# EFR32MG26B611F2048IM48 register map
Vendor: Silicon Labs; Series: EFR32; File version: B
Registers are 32-bit, read-write, reset 0x0 unless marked. A register's access mark holds for its fields unless they carry their own. Offsets are from the block's base; [hi:lo] are bit positions; lines under a group give offsets from that group; {n}, {i} and the like mark numbered series; 'fields as' and 'values as' point back to an identical list.

## GPIO_NS — GPIO_NS Registers
Base 0x5003C000
Same registers: GPIO_S 0x4003C000
0x00 IPVERSION ro reset 0x7
  [31:0] IPVERSION — ip version id
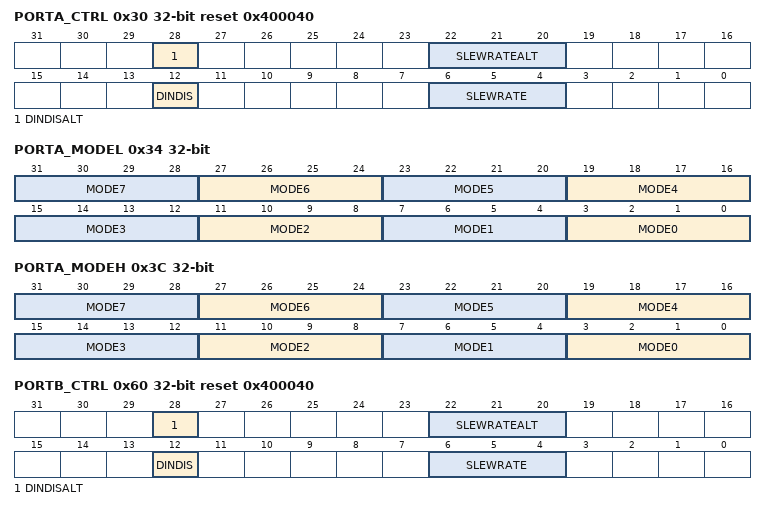
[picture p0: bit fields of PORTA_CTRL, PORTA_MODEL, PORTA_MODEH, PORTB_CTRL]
0x30 PORTA_CTRL reset 0x400040 — Port control
  [28] DINDISALT — Data In Disable Alt
  [22:20] SLEWRATEALT
  [12] DINDIS — Data In Disable
  [6:4] SLEWRATE
0x34 PORTA_MODEL — mode low
  [all] fields
    0=DISABLED (Input disabled. Pullup if DOUT is set.); 1=INPUT (Input enabled. Filter if DOUT is set.); 2=INPUTPULL (Input enabled. DOUT determines pull direction.); 3=INPUTPULLFILTER (Input enabled with filter. DOUT determines pull direction.); 4=PUSHPULL (Push-pull output.); 5=PUSHPULLALT (Push-pull using alternate control.); 6=WIREDOR (Wired-or output.); 7=WIREDORPULLDOWN (Wired-or output with pull-down.); 8=WIREDAND (Open-drain output.); 9=WIREDANDFILTER (Open-drain output with filter.); 10=WIREDANDPULLUP (Open-drain output with pullup.); 11=WIREDANDPULLUPFILTER (Open-drain output with filter and pullup.); 12=WIREDANDALT (Open-drain output using alternate control.); 13=WIREDANDALTFILTER (Open-drain output using alternate control with filter.); 14=WIREDANDALTPULLUP (Open-drain output using alternate control with pullup.); 15=WIREDANDALTPULLUPFILTER (Open-drain output using alternate control with filter and pullup.)
  [4n+3:4n] MODE{n} (n=0..7) — MODE n
0x3C PORTA_MODEH — mode high
  fields as PORTA_MODEL
0x40 PORTA_DOUT — data out
  [15:0] DOUT — Data output
0x44 PORTA_DIN ro — data in
  [15:0] DIN — Data input
0x60 PORTB_CTRL reset 0x400040 — Port control
  fields as PORTA_CTRL
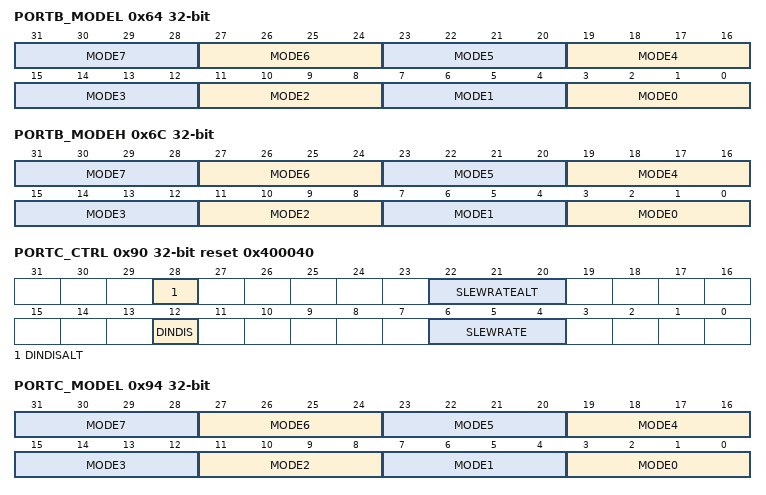
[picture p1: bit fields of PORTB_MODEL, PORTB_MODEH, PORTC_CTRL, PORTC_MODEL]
0x64 PORTB_MODEL — mode low
  fields as PORTA_MODEL
0x6C PORTB_MODEH — mode high
  fields as PORTA_MODEL
0x70 PORTB_DOUT — data out
  [15:0] DOUT — Data output
0x74 PORTB_DIN ro — data in
  [15:0] DIN — Data input
0x90 PORTC_CTRL reset 0x400040 — Port control
  fields as PORTA_CTRL
0x94 PORTC_MODEL — mode low
  fields as PORTA_MODEL
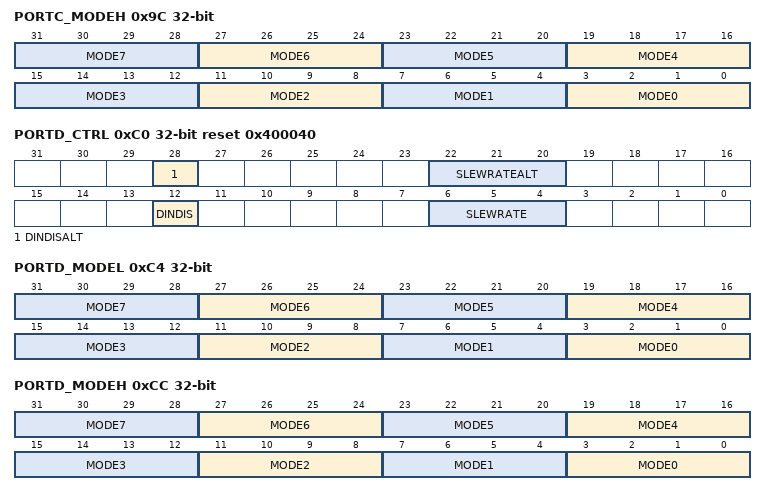
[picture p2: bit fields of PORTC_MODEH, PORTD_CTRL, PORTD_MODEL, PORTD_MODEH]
0x9C PORTC_MODEH — mode high
  fields as PORTA_MODEL
0xA0 PORTC_DOUT — data out
  [15:0] DOUT — Data output
0xA4 PORTC_DIN ro — data in
  [15:0] DIN — Data input
0xC0 PORTD_CTRL reset 0x400040 — Port control
  fields as PORTA_CTRL
0xC4 PORTD_MODEL — mode low
  fields as PORTA_MODEL
0xCC PORTD_MODEH — mode high
  fields as PORTA_MODEL
0xD0 PORTD_DOUT — data out
  [15:0] DOUT — Data output
0xD4 PORTD_DIN ro — data in
  [15:0] DIN — Data input
0x200 LCDSEGL — LCD Segment Enable Low
  [31:0] LCDSEGALLOC — LCD Segment Allocation Low
0x204 LCDSEGH — LCD Segment Enable High
  [7:0] LCDSEGALLOC — LCD Segment Allocation High
0x210 LCDCOM — LCD Common Enable
  [3:0] LCDCOMALLOC — LCD Common Allocation
0x300 LOCK wo reset 0xA534
  [15:0] LOCKKEY — Configuration Lock Key
    0xA534=UNLOCK (Unlock code)
0x310 GPIOLOCKSTATUS ro
  [0] LOCK — GPIO LOCK status
    0=UNLOCKED (Registers are unlocked); 1=LOCKED (Registers are locked)
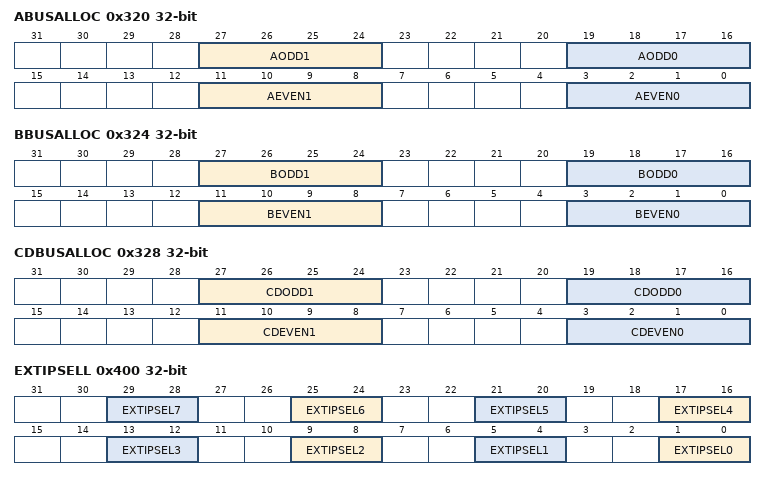
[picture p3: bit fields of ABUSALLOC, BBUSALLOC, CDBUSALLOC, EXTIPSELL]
0x320 ABUSALLOC — A Bus allocation
  [27:24] AODD1 — A Bus Odd 1
    0=TRISTATE (The bus is not allocated); 1=ADC0 (The bus is allocated to ADC0); 2=ACMP0 (The bus is allocated to ACMP0); 3=ACMP1 (The bus is allocated to ACMP1); 4=VDAC0CH1 (The bus is allocated to VDAC0 CH1); 5=VDAC1CH1 (The bus is allocated to VDAC1 CH1)
  [19:16] AODD0 — A Bus Odd 0
    0=TRISTATE (The bus is not allocated); 1=ADC0 (The bus is allocated to ADC0); 2=ACMP0 (The bus is allocated to ACMP0); 3=ACMP1 (The bus is allocated to ACMP1); 4=VDAC0CH0 (The bus is allocated to VDAC0 CH0); 5=VDAC1CH0 (The bus is allocated to VDAC1 CH0)
  [11:8] AEVEN1 — A Bus Even 1
    values as AODD1
  [3:0] AEVEN0 — A Bus Even 0
    values as AODD0
0x324 BBUSALLOC — B Bus allocation
  [27:24] BODD1 — B Bus Odd 1
    values as ABUSALLOC.AODD1
  [19:16] BODD0 — B Bus Odd 0
    values as ABUSALLOC.AODD0
  [11:8] BEVEN1 — B Bus Even 1
    values as ABUSALLOC.AODD1
  [3:0] BEVEN0 — B Bus Even 0
    values as ABUSALLOC.AODD0
0x328 CDBUSALLOC — CD Bus allocation
  [27:24] CDODD1 — CD Bus Odd 1
    values as ABUSALLOC.AODD1
  [19:16] CDODD0 — CD Bus Odd 0
    values as ABUSALLOC.AODD0
  [11:8] CDEVEN1 — CD Bus Even 1
    values as ABUSALLOC.AODD1
  [3:0] CDEVEN0 — CD Bus Even 0
    0=TRISTATE (The bus is not allocated); 1=ADC0 (The bus is allocated to ADC0); 2=ACMP0 (The bus is allocated to ACMP0); 3=ACMP1 (The bus is allocated to ACMP1); 4=VDAC0CH0 (The bus is allocated to VDAC0 CH0); 5=VDAC1CH0 (The bus is allocated to VDAC1 CH0); 11=REPEFUSE (The bus is allocated to Repair EFUSE programming voltage)
0x400 EXTIPSELL — External Interrupt Port Select Low
  [all] fields
    0=PORTA (Port A group selected); 1=PORTB (Port B group selected); 2=PORTC (Port C group selected); 3=PORTD (Port D group selected)
  [4n+1:4n] EXTIPSEL{n} (n=0..7) — External Interrupt Port Select
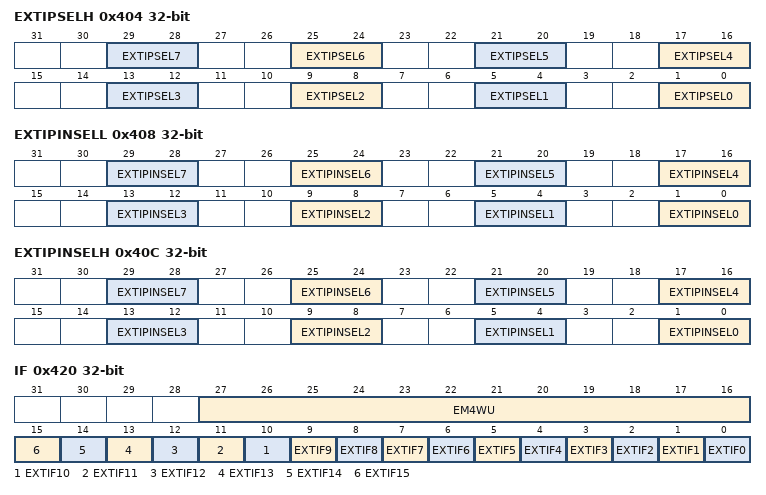
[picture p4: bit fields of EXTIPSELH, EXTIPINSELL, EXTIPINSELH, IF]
0x404 EXTIPSELH — External interrupt Port Select High
  fields as EXTIPSELL
0x408 EXTIPINSELL — External Interrupt Pin Select Low
  [all] fields
    {v}=PIN{v} (OFFSET={v}) (v=0..3)
  [4n+1:4n] EXTIPINSEL{n} (n=0..7) — External Interrupt Pin select
0x40C EXTIPINSELH — External Interrupt Pin Select High
  [all] fields
    {v}=PIN{v+8} (OFFSET={v+8}) (v=0..3)
  [4n+1:4n] EXTIPINSEL{n} (n=0..7) — External Interrupt Pin select
0x410 EXTIRISE — External Interrupt Rising Edge Trigger
  [15:0] EXTIRISE — EXT Int Rise
0x414 EXTIFALL — External Interrupt Falling Edge Trigger
  [15:0] EXTIFALL — EXT Int FALL
0x420 IF — Interrupt Flag
  [27:16] EM4WU — EM4 wake up
  [n] EXTIF{n} (n=0..15) — External Pin Flag
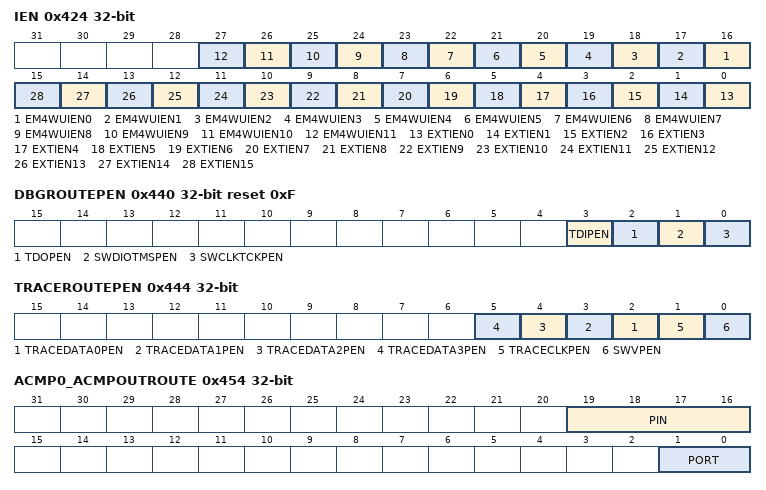
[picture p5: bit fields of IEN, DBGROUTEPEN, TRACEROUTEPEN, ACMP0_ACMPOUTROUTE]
0x424 IEN — Interrupt Enable
  [n+16] EM4WUIEN{n} (n=0..11) — EM4 Wake Up Interrupt En
  [n] EXTIEN{n} (n=0..15) — External Pin Enable
0x42C EM4WUEN
  [27:16] EM4WUEN — EM4 wake up enable
0x430 EM4WUPOL
  [27:16] EM4WUPOL — EM4 Wake-Up Polarity
0x440 DBGROUTEPEN reset 0xF
  [3] TDIPEN — JTAG Test Debug Input Pin Enable
  [2] TDOPEN — JTAG Test Debug Output Pin Enable
  [1] SWDIOTMSPEN — Route Location 0
  [0] SWCLKTCKPEN — Route Pin Enable
0x444 TRACEROUTEPEN
  [n+2] TRACEDATA{n}PEN (n=0..3) — Trace Data{n} Pin Enable
  [1] TRACECLKPEN — Trace Clk Pin Enable
  [0] SWVPEN — Serial Wire Viewer Output Pin Enable
0x450 ACMP0_ROUTEEN — ACMP0 pin enable
  [0] ACMPOUTPEN — ACMPOUT pin enable control bit
0x454 ACMP0_ACMPOUTROUTE — ACMPOUT port/pin select
  [19:16] PIN — ACMPOUT pin select register
  [1:0] PORT — ACMPOUT port select register
0x45C ACMP1_ROUTEEN — ACMP1 pin enable
  [0] ACMPOUTPEN — ACMPOUT pin enable control bit
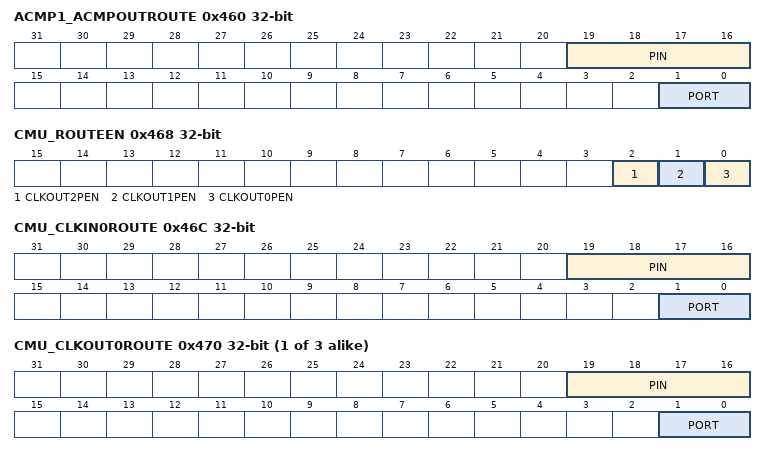
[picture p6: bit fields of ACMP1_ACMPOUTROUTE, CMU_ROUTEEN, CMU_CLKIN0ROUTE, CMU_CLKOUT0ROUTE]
0x460 ACMP1_ACMPOUTROUTE — ACMPOUT port/pin select
  fields as ACMP0_ACMPOUTROUTE
0x468 CMU_ROUTEEN — CMU pin enable
  [2] CLKOUT2PEN — CLKOUT2 pin enable control bit
  [1] CLKOUT1PEN — CLKOUT1 pin enable control bit
  [0] CLKOUT0PEN — CLKOUT0 pin enable control bit
0x46C CMU_CLKIN0ROUTE — CLKIN0 port/pin select
  [19:16] PIN — CLKIN0 pin select register
  [1:0] PORT — CLKIN0 port select register
{0x470+4i} CMU_CLKOUT{i}ROUTE (i=0..2) — CLKOUT{i} port/pin select
  [19:16] PIN — CLKOUT{i} pin select register
  [1:0] PORT — CLKOUT{i} port select register
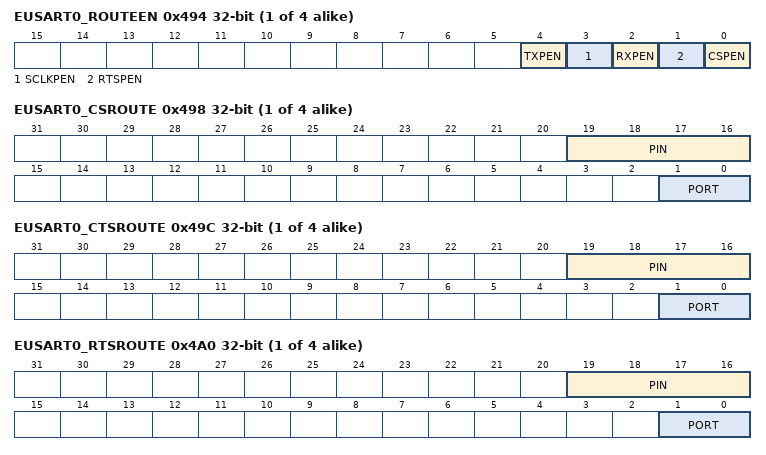
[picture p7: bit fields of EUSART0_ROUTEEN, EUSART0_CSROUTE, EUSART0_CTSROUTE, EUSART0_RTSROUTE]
{0x494+0x20*i} EUSART{i}_ROUTEEN (i=0..3) — EUSART{i} pin enable
  [4] TXPEN — TX pin enable control bit
  [3] SCLKPEN — SCLK pin enable control bit
  [2] RXPEN — RX pin enable control bit
  [1] RTSPEN — RTS pin enable control bit
  [0] CSPEN — CS pin enable control bit
{0x498+0x20*i} EUSART{i}_CSROUTE (i=0..3) — CS port/pin select
  [19:16] PIN — CS pin select register
  [1:0] PORT — CS port select register
{0x49C+0x20*i} EUSART{i}_CTSROUTE (i=0..3) — CTS port/pin select
  [19:16] PIN — CTS pin select register
  [1:0] PORT — CTS port select register
{0x4A0+0x20*i} EUSART{i}_RTSROUTE (i=0..3) — RTS port/pin select
  [19:16] PIN — RTS pin select register
  [1:0] PORT — RTS port select register
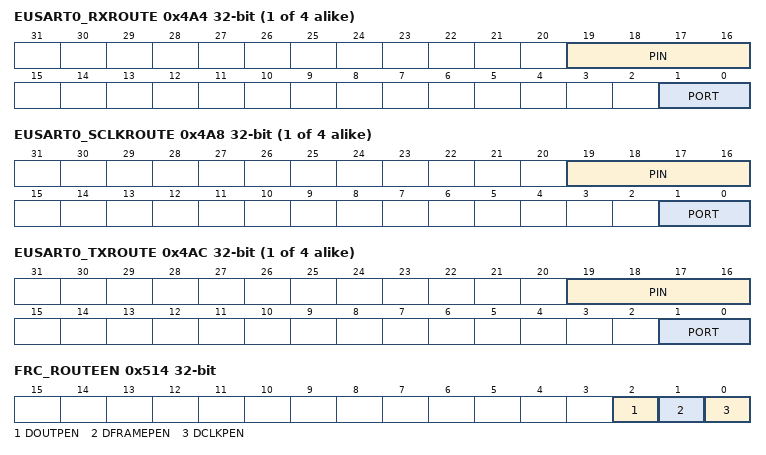
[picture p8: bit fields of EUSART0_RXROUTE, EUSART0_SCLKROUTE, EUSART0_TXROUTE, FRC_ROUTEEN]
{0x4A4+0x20*i} EUSART{i}_RXROUTE (i=0..3) — RX port/pin select
  [19:16] PIN — RX pin select register
  [1:0] PORT — RX port select register
{0x4A8+0x20*i} EUSART{i}_SCLKROUTE (i=0..3) — SCLK port/pin select
  [19:16] PIN — SCLK pin select register
  [1:0] PORT — SCLK port select register
{0x4AC+0x20*i} EUSART{i}_TXROUTE (i=0..3) — TX port/pin select
  [19:16] PIN — TX pin select register
  [1:0] PORT — TX port select register
0x514 FRC_ROUTEEN — FRC pin enable
  [2] DOUTPEN — DOUT pin enable control bit
  [1] DFRAMEPEN — DFRAME pin enable control bit
  [0] DCLKPEN — DCLK pin enable control bit
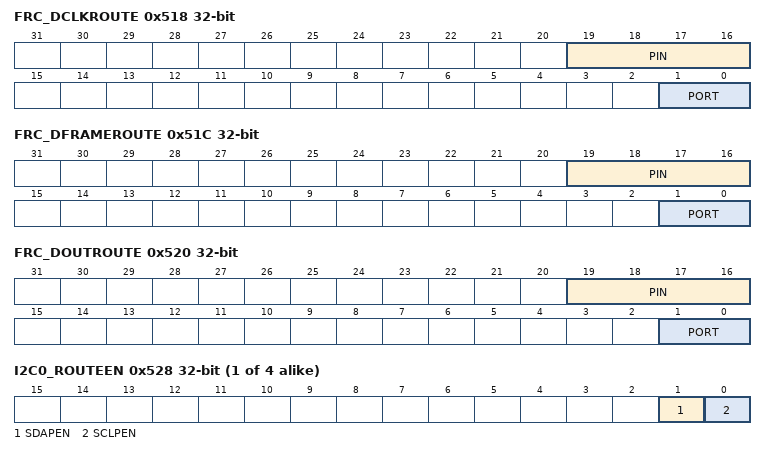
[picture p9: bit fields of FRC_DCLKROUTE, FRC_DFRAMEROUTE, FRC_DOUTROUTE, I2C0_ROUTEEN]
0x518 FRC_DCLKROUTE — DCLK port/pin select
  [19:16] PIN — DCLK pin select register
  [1:0] PORT — DCLK port select register
0x51C FRC_DFRAMEROUTE — DFRAME port/pin select
  [19:16] PIN — DFRAME pin select register
  [1:0] PORT — DFRAME port select register
0x520 FRC_DOUTROUTE — DOUT port/pin select
  [19:16] PIN — DOUT pin select register
  [1:0] PORT — DOUT port select register
{0x528+0x10*i} I2C{i}_ROUTEEN (i=0..3) — I2C{i} pin enable
  [1] SDAPEN — SDA pin enable control bit
  [0] SCLPEN — SCL pin enable control bit
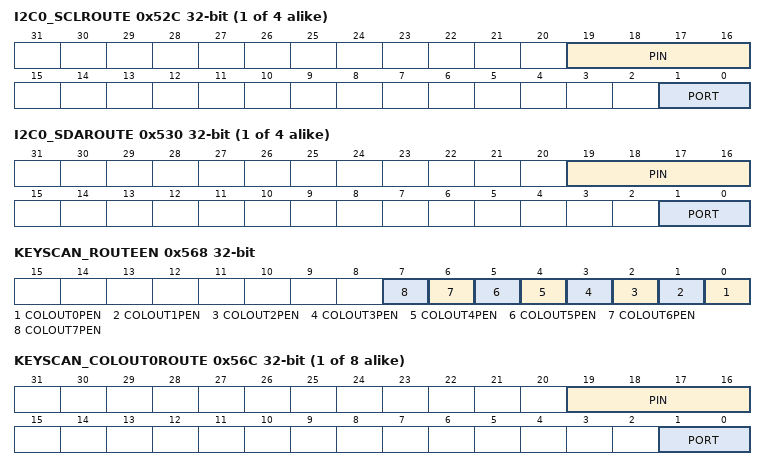
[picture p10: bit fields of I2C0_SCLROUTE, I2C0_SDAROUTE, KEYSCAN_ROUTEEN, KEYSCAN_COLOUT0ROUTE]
{0x52C+0x10*i} I2C{i}_SCLROUTE (i=0..3) — SCL port/pin select
  [19:16] PIN — SCL pin select register
  [1:0] PORT — SCL port select register
{0x530+0x10*i} I2C{i}_SDAROUTE (i=0..3) — SDA port/pin select
  [19:16] PIN — SDA pin select register
  [1:0] PORT — SDA port select register
0x568 KEYSCAN_ROUTEEN — KEYSCAN pin enable
  [n] COLOUT{n}PEN (n=0..7) — COLOUT{n} pin enable control bit
{0x56C+4i} KEYSCAN_COLOUT{i}ROUTE (i=0..7) — COLOUT{i} port/pin select
  [19:16] PIN — COLOUT{i} pin select register
  [1:0] PORT — COLOUT{i} port select register
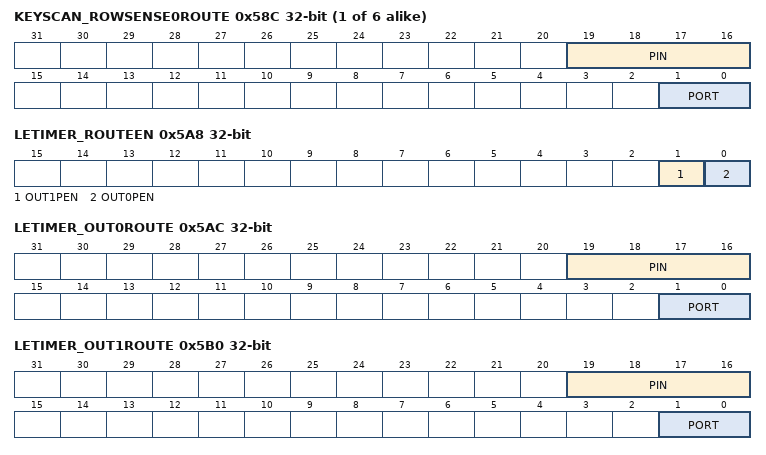
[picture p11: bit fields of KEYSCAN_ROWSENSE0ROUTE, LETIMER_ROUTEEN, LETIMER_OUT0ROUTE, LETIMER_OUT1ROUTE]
{0x58C+4i} KEYSCAN_ROWSENSE{i}ROUTE (i=0..5) — ROWSENSE{i} port/pin select
  [19:16] PIN — ROWSENSE{i} pin select register
  [1:0] PORT — ROWSENSE{i} port select register
0x5A8 LETIMER_ROUTEEN — LETIMER pin enable
  [1] OUT1PEN — OUT1 pin enable control bit
  [0] OUT0PEN — OUT0 pin enable control bit
0x5AC LETIMER_OUT0ROUTE — OUT0 port/pin select
  [19:16] PIN — OUT0 pin select register
  [1:0] PORT — OUT0 port select register
0x5B0 LETIMER_OUT1ROUTE — OUT1 port/pin select
  [19:16] PIN — OUT1 pin select register
  [1:0] PORT — OUT1 port select register
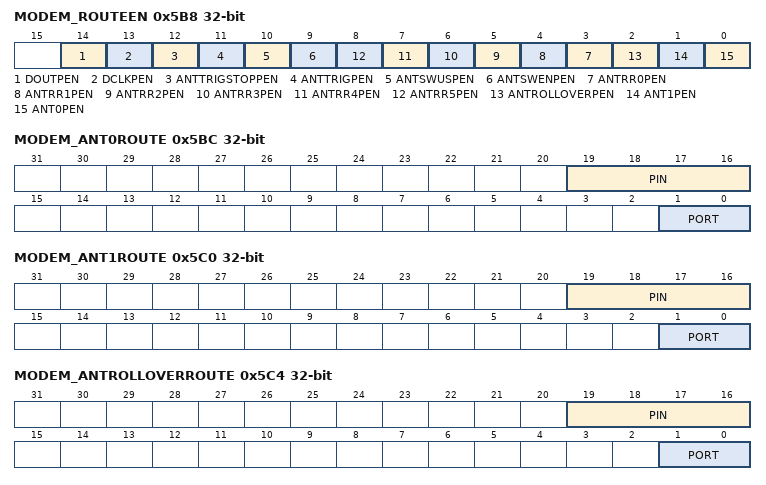
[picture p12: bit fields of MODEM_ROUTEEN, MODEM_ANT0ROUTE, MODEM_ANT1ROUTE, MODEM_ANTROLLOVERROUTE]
0x5B8 MODEM_ROUTEEN — MODEM pin enable
  [14] DOUTPEN — DOUT pin enable control bit
  [13] DCLKPEN — DCLK pin enable control bit
  [12] ANTTRIGSTOPPEN — ANTTRIGSTOP pin enable control bit
  [11] ANTTRIGPEN — ANTTRIG pin enable control bit
  [10] ANTSWUSPEN — ANTSWUS pin enable control bit
  [9] ANTSWENPEN — ANTSWEN pin enable control bit
  [n+3] ANTRR{n}PEN (n=0..5) — ANTRR{n} pin enable control bit
  [2] ANTROLLOVERPEN — ANTROLLOVER pin enable control bit
  [1] ANT1PEN — ANT1 pin enable control bit
  [0] ANT0PEN — ANT0 pin enable control bit
0x5BC MODEM_ANT0ROUTE — ANT0 port/pin select
  [19:16] PIN — ANT0 pin select register
  [1:0] PORT — ANT0 port select register
0x5C0 MODEM_ANT1ROUTE — ANT1 port/pin select
  [19:16] PIN — ANT1 pin select register
  [1:0] PORT — ANT1 port select register
0x5C4 MODEM_ANTROLLOVERROUTE — ANTROLLOVER port/pin select
  [19:16] PIN — ANTROLLOVER pin select register
  [1:0] PORT — ANTROLLOVER port select register
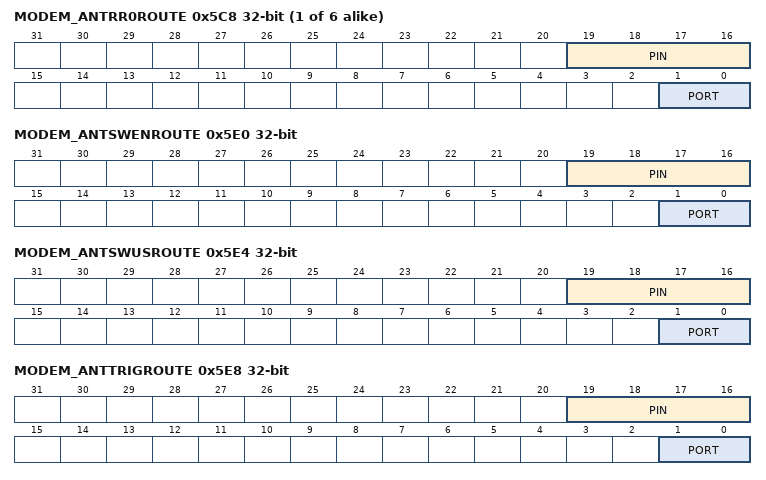
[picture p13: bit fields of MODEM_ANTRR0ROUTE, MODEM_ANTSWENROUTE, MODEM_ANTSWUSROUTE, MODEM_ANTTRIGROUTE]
{0x5C8+4i} MODEM_ANTRR{i}ROUTE (i=0..5) — ANTRR{i} port/pin select
  [19:16] PIN — ANTRR{i} pin select register
  [1:0] PORT — ANTRR{i} port select register
0x5E0 MODEM_ANTSWENROUTE — ANTSWEN port/pin select
  [19:16] PIN — ANTSWEN pin select register
  [1:0] PORT — ANTSWEN port select register
0x5E4 MODEM_ANTSWUSROUTE — ANTSWUS port/pin select
  [19:16] PIN — ANTSWUS pin select register
  [1:0] PORT — ANTSWUS port select register
0x5E8 MODEM_ANTTRIGROUTE — ANTTRIG port/pin select
  [19:16] PIN — ANTTRIG pin select register
  [1:0] PORT — ANTTRIG port select register
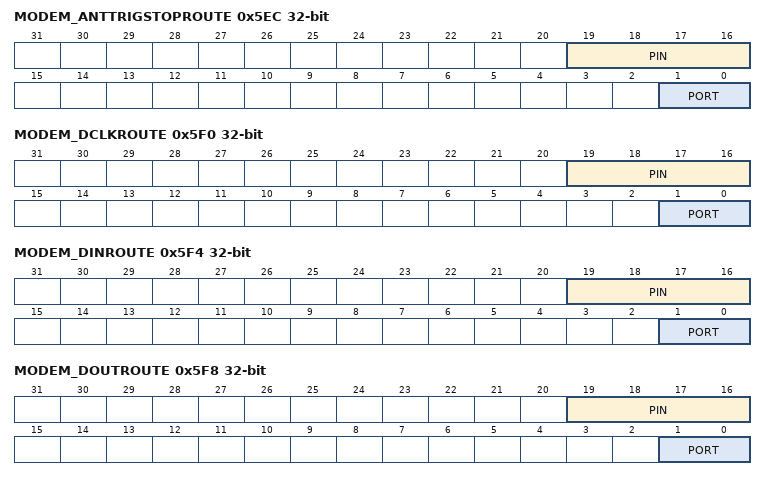
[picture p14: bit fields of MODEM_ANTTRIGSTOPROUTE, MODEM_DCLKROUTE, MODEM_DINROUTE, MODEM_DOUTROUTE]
0x5EC MODEM_ANTTRIGSTOPROUTE — ANTTRIGSTOP port/pin select
  [19:16] PIN — ANTTRIGSTOP pin select register
  [1:0] PORT — ANTTRIGSTOP port select register
0x5F0 MODEM_DCLKROUTE — DCLK port/pin select
  fields as FRC_DCLKROUTE
0x5F4 MODEM_DINROUTE — DIN port/pin select
  [19:16] PIN — DIN pin select register
  [1:0] PORT — DIN port select register
0x5F8 MODEM_DOUTROUTE — DOUT port/pin select
  fields as FRC_DOUTROUTE
0x604 PCNT0_S0INROUTE — S0IN port/pin select
  [19:16] PIN — S0IN pin select register
  [1:0] PORT — S0IN port select register
0x608 PCNT0_S1INROUTE — S1IN port/pin select
  [19:16] PIN — S1IN pin select register
  [1:0] PORT — S1IN port select register
0x610 PRS0_ROUTEEN — PRS0 pin enable
  [n+16] SYNCH{n}PEN (n=0..3) — SYNCH{n} pin enable control bit
  [n] ASYNCH{n}PEN (n=0..15) — ASYNCH{n} pin enable control bit
{0x614+4i} PRS0_ASYNCH{i}ROUTE (i=0..15) — ASYNCH{i} port/pin select
  [19:16] PIN — ASYNCH{i} pin select register
  [1:0] PORT — ASYNCH{i} port select register
{0x654+4i} PRS0_SYNCH{i}ROUTE (i=0..3) — SYNCH{i} port/pin select
  [19:16] PIN — SYNCH{i} pin select register
  [1:0] PORT — SYNCH{i} port select register
0x668 RAC_ROUTEEN — RAC pin enable
  [1] PAENPEN — PAEN pin enable control bit
  [0] LNAENPEN — LNAEN pin enable control bit
0x66C RAC_LNAENROUTE — LNAEN port/pin select
  [19:16] PIN — LNAEN pin select register
  [1:0] PORT — LNAEN port select register
0x670 RAC_PAENROUTE — PAEN port/pin select
  [19:16] PIN — PAEN pin select register
  [1:0] PORT — PAEN port select register
0x6D8 SYXO0_BUFOUTREQINASYNCROUTE — BUFOUTREQINASYNC port/pin select
  [19:16] PIN — BUFOUTREQINASYNC pin select register
  [1:0] PORT — BUFOUTREQINASYNC port select register
{0x6E0+0x20*i} TIMER{i}_ROUTEEN (i=0..4) — TIMER{i} pin enable
  [5] CCC2PEN — CDTI2 pin enable control bit
  [4] CCC1PEN — CDTI1 pin enable control bit
  [3] CCC0PEN — CDTI0 pin enable control bit
  [2] CC2PEN — CC2 pin enable control bit
  [1] CC1PEN — CC1 pin enable control bit
  [0] CC0PEN — CC0 pin enable control bit
{0x6E4+0x20*i} TIMER{i}_CC0ROUTE (i=0..9) — CC0 port/pin select
  [19:16] PIN — CC0 pin select register
  [1:0] PORT — CC0 port select register
{0x6E8+0x20*i} TIMER{i}_CC1ROUTE (i=0..9) — CC1 port/pin select
  [19:16] PIN — CC1 pin select register
  [1:0] PORT — CC1 port select register
{0x6EC+0x20*i} TIMER{i}_CC2ROUTE (i=0..9) — CC2 port/pin select
  [19:16] PIN — CC2 pin select register
  [1:0] PORT — CC2 port select register
{0x6F0+0x20*i} TIMER{i}_CDTI0ROUTE (i=0..4) — CDTI0 port/pin select
  [19:16] PIN — CDTI0 pin select register
  [1:0] PORT — CDTI0 port select register
{0x6F4+0x20*i} TIMER{i}_CDTI1ROUTE (i=0..4) — CDTI1 port/pin select
  [19:16] PIN — CDTI1 pin select register
  [1:0] PORT — CDTI1 port select register
{0x6F8+0x20*i} TIMER{i}_CDTI2ROUTE (i=0..4) — CDTI2 port/pin select
  [19:16] PIN — CDTI2 pin select register
  [1:0] PORT — CDTI2 port select register
{0x6E0+0x20*i} TIMER{i}_ROUTEEN (i=5..9) — TIMER{i} pin enable
  [5] CCC2PEN — CCC2 pin enable control bit
  [4] CCC1PEN — CCC1 pin enable control bit
  [3] CCC0PEN — CCC0 pin enable control bit
  [2] CC2PEN — CC2 pin enable control bit
  [1] CC1PEN — CC1 pin enable control bit
  [0] CC0PEN — CC0 pin enable control bit
{0x6F0+0x20*i} TIMER{i}_CCC0ROUTE (i=5..9) — CCC0 port/pin select
  [19:16] PIN — CCC0 pin select register
  [1:0] PORT — CCC0 port select register
{0x6F4+0x20*i} TIMER{i}_CCC1ROUTE (i=5..9) — CCC1 port/pin select
  [19:16] PIN — CCC1 pin select register
  [1:0] PORT — CCC1 port select register
{0x6F8+0x20*i} TIMER{i}_CCC2ROUTE (i=5..9) — CCC2 port/pin select
  [19:16] PIN — CCC2 pin select register
  [1:0] PORT — CCC2 port select register
0x820 USART0_ROUTEEN — USART0 pin enable
  [4] TXPEN — TX pin enable control bit
  [3] CLKPEN — SCLK pin enable control bit
  [2] RXPEN — RX pin enable control bit
  [1] RTSPEN — RTS pin enable control bit
  [0] CSPEN — CS pin enable control bit
{0x824+0x20*i} USART{i}_CSROUTE (i=0..2) — CS port/pin select
  fields as EUSART0_CSROUTE
{0x828+0x20*i} USART{i}_CTSROUTE (i=0..2) — CTS port/pin select
  fields as EUSART0_CTSROUTE
{0x82C+0x20*i} USART{i}_RTSROUTE (i=0..2) — RTS port/pin select
  fields as EUSART0_RTSROUTE
{0x830+0x20*i} USART{i}_RXROUTE (i=0..2) — RX port/pin select
  fields as EUSART0_RXROUTE
0x834 USART0_CLKROUTE — SCLK port/pin select
  fields as EUSART0_SCLKROUTE
{0x838+0x20*i} USART{i}_TXROUTE (i=0..2) — TX port/pin select
  fields as EUSART0_TXROUTE
0x840 USART1_ROUTEEN — USART1 pin enable
  fields as EUSART0_ROUTEEN
0x854 USART1_SCLKROUTE — SCLK port/pin select
  fields as EUSART0_SCLKROUTE
0x860 USART2_ROUTEEN — USART2 pin enable
  fields as EUSART0_ROUTEEN
0x874 USART2_SCLKROUTE — SCLK port/pin select
  fields as EUSART0_SCLKROUTE
